VERSION "nissan_frontier_2015_candidate - derived from opendbc/nissan_xterra_2011.dbc (same F-Alpha platform). Signals marked CANDIDATE need on-vehicle validation."

NS_ :

BS_:

BU_ XXX

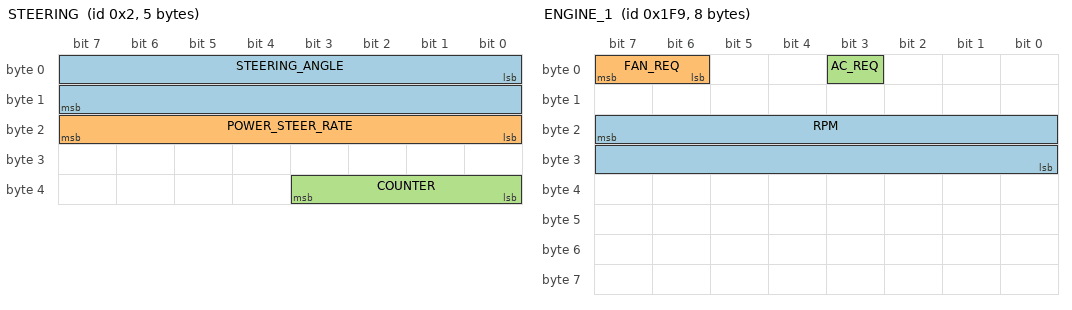
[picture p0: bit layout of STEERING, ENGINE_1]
BO_ 2 STEERING: 5 XXX
 SG_ STEERING_ANGLE : 0|16@1- (0.1,0) [-3276.8|3276.7] "deg" XXX
 SG_ POWER_STEER_RATE : 23|8@0+ (1,0) [0|255] "" XXX
 SG_ COUNTER : 35|4@0+ (1,0) [0|15] "" XXX

BO_ 352 THROTTLE: 7 XXX
 SG_ THROTTLE_POSITION : 24|8@1+ (0.392,0) [0|100] "%" XXX
 SG_ THROTTLE_POSITION_INV : 40|8@1+ (-0.392,99.96) [0|100] "%" XXX

BO_ 384 ENGINE_RPM_ALT: 8 XXX
 SG_ RPM : 7|16@0+ (0.125,0) [0|8191.875] "rpm" XXX

BO_ 505 ENGINE_1: 8 XXX
 SG_ RPM : 23|16@0+ (0.125,0) [0|8191.875] "rpm" XXX
 SG_ FAN_REQ : 6|2@1+ (1,0) [0|3] "" XXX
 SG_ AC_REQ : 3|1@1+ (1,0) [0|1] "" XXX

BO_ 640 SPEED: 8 XXX
 SG_ SPEED : 39|16@0+ (0.01,0) [0|655.35] "mph" XXX

BO_ 644 ABS_1: 8 XXX
 SG_ WHEEL_1 : 7|16@0+ (0.01,0) [0|655.35] "km/h" XXX
 SG_ WHEEL_2 : 23|16@0+ (0.01,0) [0|655.35] "km/h" XXX

BO_ 645 ABS_2: 8 XXX
 SG_ WHEEL_3 : 7|16@0+ (0.01,0) [0|655.35] "km/h" XXX
 SG_ WHEEL_4 : 23|16@0+ (0.01,0) [0|655.35] "km/h" XXX

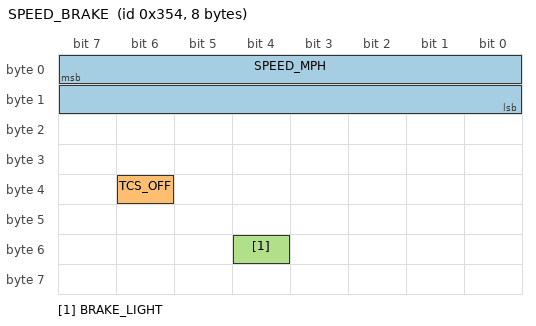
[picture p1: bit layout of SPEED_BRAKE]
BO_ 852 SPEED_BRAKE: 8 XXX
 SG_ SPEED_MPH : 7|16@0+ (0.0066,0) [0|432.3] "mph" XXX
 SG_ TCS_OFF : 38|1@0+ (1,0) [0|1] "" XXX
 SG_ BRAKE_LIGHT : 52|1@0+ (1,0) [0|1] "" XXX

BO_ 861 BCM: 8 XXX
 SG_ BRAKE_SWITCH : 36|1@1+ (1,0) [0|1] "" XXX

BO_ 1361 ENGINE_5: 8 XXX
 SG_ COOLANT_TEMP : 0|8@1+ (1,-45) [-45|210] "degC" XXX

BO_ 1408 ENGINE_6: 8 XXX
 SG_ RPM_COARSE : 7|16@0+ (1.5,0) [0|98302.5] "rpm" XXX
 SG_ OIL_TEMP : 32|8@1+ (1,-40) [-40|215] "degC" XXX

BO_ 375 SHIFT_TORQUE_REQ: 8 XXX
 SG_ TORQUE_REDUCE_REQ : 32|8@1+ (1,0) [0|255] "" XXX

BO_ 386 ENGINE_TORQUE: 8 XXX
 SG_ ENGINE_TORQUE : 32|8@1+ (1,0) [0|255] "" XXX

BO_ 1057 GEARBOX: 3 XXX
 SG_ GEAR_SELECTOR : 0|8@1+ (1,0) [0|32] "" XXX

BO_ 1477 MILEAGE: 8 XXX

CM_ SG_ 505 RPM "CONFIRMED on-vehicle: big-endian (Motorola), 0.125 rpm/bit. Idle raw ~5650 = ~706 rpm. NOTE: Xterra DBC had this little-endian, which is WRONG for the Frontier.";
CM_ SG_ 384 RPM "CONFIRMED: same RPM value mirrored here in bytes 0-1, big-endian.";
CM_ SG_ 2 STEERING_ANGLE "CONFIRMED on-vehicle: little-endian signed, 0.1 deg/bit, offset 0. Reads ~0 centered; swept -613..+611 deg. (Endianness is per-signal here: RPM is big-endian, this is little-endian.)";
CM_ SG_ 352 THROTTLE_POSITION "CONFIRMED (discovery, not in Xterra DBC): 0x160 byte3, 0 at idle (throttle closed), rises with pedal blips and leads RPM. Scale 0.392 assumed (0-255=0-100%); refine at wide-open throttle.";
CM_ SG_ 352 THROTTLE_POSITION_INV "Redundant TPS track: raw byte5 = 255 - byte3. Should read same % as THROTTLE_POSITION (dual-track sensor validation). Accel PEDAL candidate also at 0x160 byte4 (idle ~8, reaches 200).";
CM_ SG_ 1361 COOLANT_TEMP "HIGH CONFIDENCE: read ~46-47 degC at idle in the baseline capture.";
CM_ SG_ 1057 GEAR_SELECTOR "CONFIRMED (discovery): 0x421 byte0. P=0x08 (baseline/park), R=0x10, N=0x18, D=0x20 (+8 each); 0x00 flickers between detents.";
CM_ SG_ 375 TORQUE_REDUCE_REQ "CANDIDATE (2 upshifts): 0x177 byte4 = 0 except a ~150ms pulse centered on each upshift; magnitude tracks shift firmness (0x9A hard, 0x4D light). Likely the TCU->ECM torque-reduction request. Scale raw pending more events.";
CM_ SG_ 386 ENGINE_TORQUE "CANDIDATE (2 upshifts): 0x182 byte4 = engine torque/load. Pegged 0xFF under hard load, dips ~50% exactly as RPM falls during the shift; rose with throttle earlier. The ECM side of the shift torque handshake. Scale raw pending.";

VAL_ 1057 GEAR_SELECTOR 8 "P" 16 "R" 24 "N" 32 "D" 0 "SHIFTING" ;
CM_ SG_ 640 SPEED "CONFIRMED on-vehicle: big-endian bytes4-5, unit is 0.01 MPH (peak raw 1091 = 10.9 mph vs driver-reported ~11 mph). Note: this is mph, while the ABS wheels below are km/h.";
CM_ SG_ 644 WHEEL_1 "CONFIRMED: 0x284/0x285 all four wheels big-endian, 0.01 km/h (peak raw 1858 = 18.6 km/h = 11.5 mph, matches ~11 mph). All four agree straight, split slightly in turns.";
CM_ SG_ 852 BRAKE_LIGHT "CONFIRMED on-vehicle: byte6 toggles 0x04<->0x14 (bit 52) on brake press.";
CM_ SG_ 861 BRAKE_SWITCH "CONFIRMED: BCM byte4 bit4 toggles 0x00<->0x10 on brake press (was an undecoded message). Candidate brake flags also at 0x180 b7 bit0 and 0x182 b6 bit6.";
